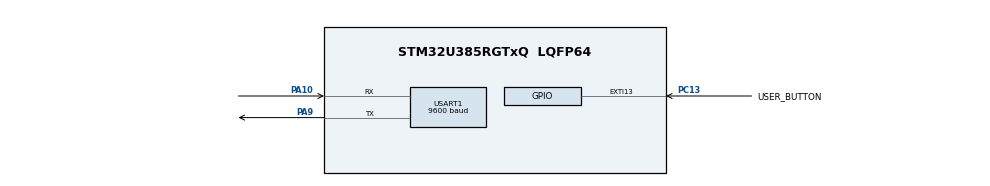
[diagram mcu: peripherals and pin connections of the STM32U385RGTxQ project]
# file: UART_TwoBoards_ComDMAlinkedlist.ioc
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CORTEX_M33_NS.userName=CORTEX_M33
GPDMA1.LINKALLOCATEDPORT_GPDMACH0=DMA_LINK_ALLOCATED_PORT1
GPDMA1.LINKALLOCATEDPORT_GPDMACH1=DMA_LINK_ALLOCATED_PORT1
Linkedlist.MDMA_Channel0.GP_SW.0.BlkHWRequest=DMA_BREQ_SINGLE_BURST
Linkedlist.MDMA_Channel0.GP_SW.0.DataHandling=NONE
Linkedlist.MDMA_Channel0.GP_SW.0.DataSize=0
Linkedlist.MDMA_Channel0.GP_SW.0.DestBurstLength=1
Linkedlist.MDMA_Channel0.GP_SW.0.DestDataWidth=DMA_DEST_DATAWIDTH_BYTE
Linkedlist.MDMA_Channel0.GP_SW.0.DestInc=DMA_DINC_FIXED
Linkedlist.MDMA_Channel0.GP_SW.0.Direction=DMA_MEMORY_TO_PERIPH
Linkedlist.MDMA_Channel0.GP_SW.0.DstAddress=0
Linkedlist.MDMA_Channel0.GP_SW.0.Instance=MDMA_Channel0
Linkedlist.MDMA_Channel0.GP_SW.0.LL_MASTERDMA=GPDMA
Linkedlist.MDMA_Channel0.GP_SW.0.LL_NAME=UART_Tx_Queue
Linkedlist.MDMA_Channel0.GP_SW.0.LL_TYPE=LINEAR
Linkedlist.MDMA_Channel0.GP_SW.0.Mode=DMA_NORMAL
Linkedlist.MDMA_Channel0.GP_SW.0.NODE_NAME=Node1_tx
Linkedlist.MDMA_Channel0.GP_SW.0.Requestforcodegen=GPDMA1_REQUEST_USART1_TX
Linkedlist.MDMA_Channel0.GP_SW.0.SrcAddress=0
Linkedlist.MDMA_Channel0.GP_SW.0.SrcBurstLength=1
Linkedlist.MDMA_Channel0.GP_SW.0.SrcDataWidth=DMA_SRC_DATAWIDTH_BYTE
Linkedlist.MDMA_Channel0.GP_SW.0.SrcInc=DMA_SINC_INCREMENTED
Linkedlist.MDMA_Channel0.GP_SW.0.TransferAllocatedPortSrc=DMA_SRC_ALLOCATED_PORT0
Linkedlist.MDMA_Channel0.GP_SW.0.TransferEventMode=DMA_TCEM_LAST_LL_ITEM_TRANSFER
Linkedlist.MDMA_Channel0.GP_SW.0.TriggerPolarity=DMA_TRIG_POLARITY_MASKED
Linkedlist.MDMA_Channel0.GP_SW.1.BlkHWRequest=DMA_BREQ_SINGLE_BURST
Linkedlist.MDMA_Channel0.GP_SW.1.DataHandling=NONE
Linkedlist.MDMA_Channel0.GP_SW.1.DataSize=128
Linkedlist.MDMA_Channel0.GP_SW.1.DestBurstLength=1
Linkedlist.MDMA_Channel0.GP_SW.1.DestDataWidth=DMA_DEST_DATAWIDTH_BYTE
Linkedlist.MDMA_Channel0.GP_SW.1.DestInc=DMA_DINC_FIXED
Linkedlist.MDMA_Channel0.GP_SW.1.Direction=DMA_MEMORY_TO_PERIPH
Linkedlist.MDMA_Channel0.GP_SW.1.DstAddress=(uint32_t)&huart1.Instance->TDR
Linkedlist.MDMA_Channel0.GP_SW.1.Instance=MDMA_Channel0
Linkedlist.MDMA_Channel0.GP_SW.1.LL_MASTERDMA=GPDMA
Linkedlist.MDMA_Channel0.GP_SW.1.LL_NAME=UART_Tx_Queue
Linkedlist.MDMA_Channel0.GP_SW.1.LL_TYPE=LINEAR
Linkedlist.MDMA_Channel0.GP_SW.1.Mode=DMA_NORMAL
Linkedlist.MDMA_Channel0.GP_SW.1.NODE_NAME=Node2_tx
Linkedlist.MDMA_Channel0.GP_SW.1.Requestforcodegen=GPDMA1_REQUEST_USART1_TX
Linkedlist.MDMA_Channel0.GP_SW.1.SrcAddress=(uint32_t) aTxBuffer1
Linkedlist.MDMA_Channel0.GP_SW.1.SrcBurstLength=1
Linkedlist.MDMA_Channel0.GP_SW.1.SrcDataWidth=DMA_SRC_DATAWIDTH_BYTE
Linkedlist.MDMA_Channel0.GP_SW.1.SrcInc=DMA_SINC_INCREMENTED
Linkedlist.MDMA_Channel0.GP_SW.1.TransferAllocatedPortSrc=DMA_SRC_ALLOCATED_PORT0
Linkedlist.MDMA_Channel0.GP_SW.1.TransferEventMode=DMA_TCEM_LAST_LL_ITEM_TRANSFER
Linkedlist.MDMA_Channel0.GP_SW.1.TriggerPolarity=DMA_TRIG_POLARITY_MASKED
Linkedlist.MDMA_Channel0.GP_SW.2.BlkHWRequest=DMA_BREQ_SINGLE_BURST
Linkedlist.MDMA_Channel0.GP_SW.2.DataHandling=NONE
Linkedlist.MDMA_Channel0.GP_SW.2.DataSize=128
Linkedlist.MDMA_Channel0.GP_SW.2.DestBurstLength=1
Linkedlist.MDMA_Channel0.GP_SW.2.DestDataWidth=DMA_DEST_DATAWIDTH_BYTE
Linkedlist.MDMA_Channel0.GP_SW.2.DestInc=DMA_DINC_FIXED
Linkedlist.MDMA_Channel0.GP_SW.2.Direction=DMA_MEMORY_TO_PERIPH
Linkedlist.MDMA_Channel0.GP_SW.2.DstAddress=(uint32_t)&huart1.Instance->TDR
Linkedlist.MDMA_Channel0.GP_SW.2.Instance=MDMA_Channel0
Linkedlist.MDMA_Channel0.GP_SW.2.LL_MASTERDMA=GPDMA
Linkedlist.MDMA_Channel0.GP_SW.2.LL_NAME=UART_Tx_Queue
Linkedlist.MDMA_Channel0.GP_SW.2.LL_TYPE=LINEAR
Linkedlist.MDMA_Channel0.GP_SW.2.Mode=DMA_NORMAL
Linkedlist.MDMA_Channel0.GP_SW.2.NODE_NAME=Node3_tx
Linkedlist.MDMA_Channel0.GP_SW.2.Requestforcodegen=GPDMA1_REQUEST_USART1_TX
Linkedlist.MDMA_Channel0.GP_SW.2.SrcAddress=(uint32_t) aTxBuffer2
Linkedlist.MDMA_Channel0.GP_SW.2.SrcBurstLength=1
Linkedlist.MDMA_Channel0.GP_SW.2.SrcDataWidth=DMA_SRC_DATAWIDTH_BYTE
Linkedlist.MDMA_Channel0.GP_SW.2.SrcInc=DMA_SINC_INCREMENTED
Linkedlist.MDMA_Channel0.GP_SW.2.TransferAllocatedPortSrc=DMA_SRC_ALLOCATED_PORT0
Linkedlist.MDMA_Channel0.GP_SW.2.TransferEventMode=DMA_TCEM_LAST_LL_ITEM_TRANSFER
Linkedlist.MDMA_Channel0.GP_SW.2.TriggerPolarity=DMA_TRIG_POLARITY_MASKED
Linkedlist.MDMA_Channel0.Request0=GP_SW
Linkedlist.MDMA_Channel0.Request1=GP_SW
Linkedlist.MDMA_Channel0.Request2=GP_SW
Linkedlist.MDMA_Channel0.RequestsNb=3
Linkedlist.MDMA_Channel1.GP_SW.0.BlkHWRequest=DMA_BREQ_SINGLE_BURST
Linkedlist.MDMA_Channel1.GP_SW.0.DataHandling=NONE
Linkedlist.MDMA_Channel1.GP_SW.0.DataSize=0
Linkedlist.MDMA_Channel1.GP_SW.0.DestBurstLength=1
Linkedlist.MDMA_Channel1.GP_SW.0.DestDataWidth=DMA_DEST_DATAWIDTH_BYTE
Linkedlist.MDMA_Channel1.GP_SW.0.DestInc=DMA_DINC_INCREMENTED
Linkedlist.MDMA_Channel1.GP_SW.0.Direction=DMA_PERIPH_TO_MEMORY
Linkedlist.MDMA_Channel1.GP_SW.0.DstAddress=0
Linkedlist.MDMA_Channel1.GP_SW.0.Instance=MDMA_Channel1
Linkedlist.MDMA_Channel1.GP_SW.0.LL_MASTERDMA=GPDMA
Linkedlist.MDMA_Channel1.GP_SW.0.LL_NAME=UART_Rx_Queue
Linkedlist.MDMA_Channel1.GP_SW.0.LL_TYPE=LINEAR
Linkedlist.MDMA_Channel1.GP_SW.0.Mode=DMA_NORMAL
Linkedlist.MDMA_Channel1.GP_SW.0.NODE_NAME=Node1_rx
Linkedlist.MDMA_Channel1.GP_SW.0.Requestforcodegen=GPDMA1_REQUEST_USART1_RX
Linkedlist.MDMA_Channel1.GP_SW.0.SrcAddress=0
Linkedlist.MDMA_Channel1.GP_SW.0.SrcBurstLength=1
Linkedlist.MDMA_Channel1.GP_SW.0.SrcDataWidth=DMA_SRC_DATAWIDTH_BYTE
Linkedlist.MDMA_Channel1.GP_SW.0.SrcInc=DMA_SINC_FIXED
Linkedlist.MDMA_Channel1.GP_SW.0.TransferAllocatedPortSrc=DMA_SRC_ALLOCATED_PORT0
Linkedlist.MDMA_Channel1.GP_SW.0.TransferEventMode=DMA_TCEM_LAST_LL_ITEM_TRANSFER
Linkedlist.MDMA_Channel1.GP_SW.0.TriggerPolarity=DMA_TRIG_POLARITY_MASKED
Linkedlist.MDMA_Channel1.GP_SW.1.BlkHWRequest=DMA_BREQ_SINGLE_BURST
Linkedlist.MDMA_Channel1.GP_SW.1.DataHandling=NONE
Linkedlist.MDMA_Channel1.GP_SW.1.DataSize=128
Linkedlist.MDMA_Channel1.GP_SW.1.DestBurstLength=1
Linkedlist.MDMA_Channel1.GP_SW.1.DestDataWidth=DMA_DEST_DATAWIDTH_BYTE
Linkedlist.MDMA_Channel1.GP_SW.1.DestInc=DMA_DINC_INCREMENTED
Linkedlist.MDMA_Channel1.GP_SW.1.Direction=DMA_PERIPH_TO_MEMORY
Linkedlist.MDMA_Channel1.GP_SW.1.DstAddress=(uint32_t) aRxBuffer1
Linkedlist.MDMA_Channel1.GP_SW.1.Instance=MDMA_Channel1
Linkedlist.MDMA_Channel1.GP_SW.1.LL_MASTERDMA=GPDMA
Linkedlist.MDMA_Channel1.GP_SW.1.LL_NAME=UART_Rx_Queue
Linkedlist.MDMA_Channel1.GP_SW.1.LL_TYPE=LINEAR
Linkedlist.MDMA_Channel1.GP_SW.1.Mode=DMA_NORMAL
Linkedlist.MDMA_Channel1.GP_SW.1.NODE_NAME=Node2_rx
Linkedlist.MDMA_Channel1.GP_SW.1.Requestforcodegen=GPDMA1_REQUEST_USART1_RX
Linkedlist.MDMA_Channel1.GP_SW.1.SrcAddress=(uint32_t)&huart1.Instance->RDR
Linkedlist.MDMA_Channel1.GP_SW.1.SrcBurstLength=1
Linkedlist.MDMA_Channel1.GP_SW.1.SrcDataWidth=DMA_SRC_DATAWIDTH_BYTE
Linkedlist.MDMA_Channel1.GP_SW.1.SrcInc=DMA_SINC_FIXED
Linkedlist.MDMA_Channel1.GP_SW.1.TransferAllocatedPortSrc=DMA_SRC_ALLOCATED_PORT0
Linkedlist.MDMA_Channel1.GP_SW.1.TransferEventMode=DMA_TCEM_LAST_LL_ITEM_TRANSFER
Linkedlist.MDMA_Channel1.GP_SW.1.TriggerPolarity=DMA_TRIG_POLARITY_MASKED
Linkedlist.MDMA_Channel1.GP_SW.2.BlkHWRequest=DMA_BREQ_SINGLE_BURST
Linkedlist.MDMA_Channel1.GP_SW.2.DataHandling=NONE
Linkedlist.MDMA_Channel1.GP_SW.2.DataSize=128
Linkedlist.MDMA_Channel1.GP_SW.2.DestBurstLength=1
Linkedlist.MDMA_Channel1.GP_SW.2.DestDataWidth=DMA_DEST_DATAWIDTH_BYTE
Linkedlist.MDMA_Channel1.GP_SW.2.DestInc=DMA_DINC_INCREMENTED
Linkedlist.MDMA_Channel1.GP_SW.2.Direction=DMA_PERIPH_TO_MEMORY
Linkedlist.MDMA_Channel1.GP_SW.2.DstAddress=(uint32_t) aRxBuffer2
Linkedlist.MDMA_Channel1.GP_SW.2.Instance=MDMA_Channel1
Linkedlist.MDMA_Channel1.GP_SW.2.LL_MASTERDMA=GPDMA
Linkedlist.MDMA_Channel1.GP_SW.2.LL_NAME=UART_Rx_Queue
Linkedlist.MDMA_Channel1.GP_SW.2.LL_TYPE=LINEAR
Linkedlist.MDMA_Channel1.GP_SW.2.Mode=DMA_NORMAL
Linkedlist.MDMA_Channel1.GP_SW.2.NODE_NAME=Node3_rx
Linkedlist.MDMA_Channel1.GP_SW.2.Requestforcodegen=GPDMA1_REQUEST_USART1_RX
Linkedlist.MDMA_Channel1.GP_SW.2.SrcAddress=(uint32_t)&huart1.Instance->RDR
Linkedlist.MDMA_Channel1.GP_SW.2.SrcBurstLength=1
Linkedlist.MDMA_Channel1.GP_SW.2.SrcDataWidth=DMA_SRC_DATAWIDTH_BYTE
Linkedlist.MDMA_Channel1.GP_SW.2.SrcInc=DMA_SINC_FIXED
Linkedlist.MDMA_Channel1.GP_SW.2.TransferAllocatedPortSrc=DMA_SRC_ALLOCATED_PORT0
Linkedlist.MDMA_Channel1.GP_SW.2.TransferEventMode=DMA_TCEM_LAST_LL_ITEM_TRANSFER
Linkedlist.MDMA_Channel1.GP_SW.2.TriggerPolarity=DMA_TRIG_POLARITY_MASKED
Linkedlist.MDMA_Channel1.Request0=GP_SW
Linkedlist.MDMA_Channel1.Request1=GP_SW
Linkedlist.MDMA_Channel1.Request2=GP_SW
Linkedlist.MDMA_Channel1.RequestsNb=3
Linkedlist.RequestSet0=MDMA_Channel0
Linkedlist.RequestSet1=MDMA_Channel1
Linkedlist.RequestSetsNb=2
Mcu.Family=STM32U3
Mcu.Name=STM32U385RGTxQ
Mcu.Package=LQFP64
NVIC.EXTI13_IRQn=true\:0\:0\:false\:false\:true\:true\:true\:true
NVIC.GPDMA1_Channel0_IRQn=true\:0\:0\:false\:false\:true\:true\:true\:true
NVIC.GPDMA1_Channel1_IRQn=true\:0\:0\:false\:false\:true\:true\:true\:true
NVIC.PriorityGroup=NVIC_PRIORITYGROUP_4
NVIC.USART1_IRQn=true\:0\:0\:false\:false\:true\:true\:true\:true
PA10.GPIO_PuPd=GPIO_PULLUP
PA10.GPIO_Speed=GPIO_SPEED_FREQ_VERY_HIGH
PA10.Mode=Asynchronous
PA10.Signal=USART1_RX
PA9.GPIO_PuPd=GPIO_PULLUP
PA9.GPIO_Speed=GPIO_SPEED_FREQ_VERY_HIGH
PA9.Mode=Asynchronous
PA9.Signal=USART1_TX
PC13.GPIO_Label=USER_BUTTON
PC13.GPIO_ModeDefaultEXTI=GPIO_MODE_IT_RISING
PC13.GPIO_PuPd=GPIO_PULLDOWN
PC13.Signal=GPXTI13
ProjectManager.HeapSize=0x200
ProjectManager.StackSize=0x400
ProjectManager.TargetToolchain=EWARM V9.20
RCC.ADCFreq_Value=96000000
RCC.AHBFreq_Value=96000000
RCC.APB1Freq_Value=96000000
RCC.APB1TimFreq_Value=96000000
RCC.APB2Freq_Value=96000000
RCC.APB2TimFreq_Value=96000000
RCC.APB3Freq_Value=96000000
RCC.CortexFreq_Value=12000000
RCC.HCLKFreq_Value=96000000
RCC.HSE_VALUE=16000000
RCC.HSI48_VALUE=48000000
RCC.HSI_VALUE=16000000
RCC.LSE_VALUE=32768
RCC.LSIDIV_VALUE=32000
RCC.MSISDIV=RCC_MSI_DIV1
RCC.SYSCLKFreq_VALUE=96000000
RCC.USBFreq_Value=96000000
USART1.BaudRate=9600
USART1.ClockPrescaler=PRESCALER_DIV1
USART1.OneBitSampling=UART_ONE_BIT_SAMPLE_DISABLE
USART1.VirtualMode-Asynchronous=VM_ASYNC
VP_GPDMA1_VS_GPDMACH0.Mode=LINKEDLIST_GPDMACH0
VP_GPDMA1_VS_GPDMACH1.Mode=LINKEDLIST_GPDMACH1
VP_ICACHE_VS_ICACHE.Mode=DirectMappedCache
VP_PWR_VS_DBSignals.Mode=DisableDeadBatterySignals
VP_PWR_VS_LPOM.Mode=PowerOptimisation
VP_PWR_VS_SECSignals.Mode=Security/Privilege
board=custom

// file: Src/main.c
/* USER CODE BEGIN Header */
/**
  ******************************************************************************
  * @file           : main.c
  * @brief          : Main program body
  ******************************************************************************
  * @attention
  *
  * Copyright (c) 2024 STMicroelectronics.
  * All rights reserved.
  *
  * This software is licensed under terms that can be found in the LICENSE file
  * in the root directory of this software component.
  * If no LICENSE file comes with this software, it is provided AS-IS.
  *
  ******************************************************************************
  */
/* USER CODE END Header */
#include "main.h"

/* USER CODE BEGIN Includes */
#include "linked_list.h"
/* USER CODE END Includes */

/* USER CODE BEGIN PD */
//#define TRANSMITTER_BOARD
/* USER CODE END PD */

DMA_HandleTypeDef handle_GPDMA1_Channel1;
DMA_HandleTypeDef handle_GPDMA1_Channel0;

UART_HandleTypeDef huart1;

/* USER CODE BEGIN PV */
__IO ITStatus UartReady = RESET;
__IO uint32_t UserButtonStatus = 0;  /* set to 1 after User Button interrupt  */
extern DMA_QListTypeDef UART_Tx_Queue;
extern DMA_QListTypeDef UART_Rx_Queue;

/* Buffers used for transmission :
   Size should be a Multiple of cache line size (32 bytes) */
ALIGN_32BYTES (uint8_t aTxBuffer0[]) = "0*****UART_TwoBoards communication based on DMA Linkedlist*****  *****UART_TwoBoards communication based on DMA Linkedlist*****0";
ALIGN_32BYTES (uint8_t aTxBuffer1[]) = "1*****UART_TwoBoards communication based on DMA Linkedlist*****  *****UART_TwoBoards communication based on DMA Linkedlist*****1";
ALIGN_32BYTES (uint8_t aTxBuffer2[]) = "2*****UART_TwoBoards communication based on DMA Linkedlist*****  *****UART_TwoBoards communication based on DMA Linkedlist*****2";

/* Buffer used for reception :
   Size should be a Multiple of cache line size (32 bytes) */
ALIGN_32BYTES (uint8_t aRxBuffer0[RXBUFFERSIZE]);
ALIGN_32BYTES (uint8_t aRxBuffer1[RXBUFFERSIZE]);
ALIGN_32BYTES (uint8_t aRxBuffer2[RXBUFFERSIZE]);
/* USER CODE END PV */

void SystemClock_Config(void);
static void MX_GPIO_Init(void);
static void MX_GPDMA1_Init(void);
static void MX_USART1_UART_Init(void);
static void MX_ICACHE_Init(void);
/* USER CODE BEGIN PFP */
static uint16_t Buffercmp(uint8_t* pBuffer1, uint8_t* pBuffer2, uint16_t BufferLength);
/* USER CODE END PFP */

int main(void)
{

  /* USER CODE BEGIN 1 */

  /* STM32U3xx HAL library initialization:
       - Configure the Flash prefetch
       - Configure the Systick to generate an interrupt each 1 msec
       - Set NVIC Group Priority to 3
       - Low Level Initialization
     */
  /* USER CODE END 1 */

  /* MCU Configuration--------------------------------------------------------*/

  /* Reset of all peripherals, Initializes the Flash interface and the Systick. */
  HAL_Init();

  /* Configure the system clock */
  SystemClock_Config();

  /* USER CODE BEGIN SysInit */
  /* Configure LD2 */
  BSP_LED_Init(LD2);

  /* USER CODE END SysInit */

  /* Initialize all configured peripherals */
  MX_GPIO_Init();
  MX_GPDMA1_Init();
  MX_USART1_UART_Init();
  MX_ICACHE_Init();
  /* USER CODE BEGIN 2 */

  MX_UART_Tx_Queue_Config();
  MX_UART_Rx_Queue_Config();
  /* Link UART queue to DMA channel */
  HAL_DMAEx_List_LinkQ(&handle_GPDMA1_Channel1, &UART_Tx_Queue);

  /* Associate the initialized GPDMA handle to the UART handle */
  __HAL_LINKDMA(&huart1, hdmatx, handle_GPDMA1_Channel1);

  /* Link UART queue to DMA channel */
  HAL_DMAEx_List_LinkQ(&handle_GPDMA1_Channel0, &UART_Rx_Queue);

  /* Associate the initialized GPDMA handle to the UART handle */
  __HAL_LINKDMA(&huart1, hdmarx, handle_GPDMA1_Channel0);

#ifdef TRANSMITTER_BOARD

  /* Configure User push-button in Interrupt mode */
  BSP_PB_Init(BUTTON_USER, BUTTON_MODE_EXTI);

  /* Wait for User push-button press before starting the Communication.
     In the meantime, LD2 is blinking */
  while(UserButtonStatus == 0)
  {
      /* Toggle LD2 */
      BSP_LED_Toggle(LD2);
      HAL_Delay(100);
  }

  BSP_LED_Off(LD2);

  /* The board sends the message and expects to receive it back */

  /*##-2- Start the transmission process #####################################*/
  /* While the UART in reception process, user can transmit data through
     "aTxBuffer" buffer */
  if(HAL_UART_Transmit_DMA(&huart1, (uint8_t*)aTxBuffer0, TXBUFFERSIZE)!= HAL_OK)
  {
    Error_Handler();
  }

  /*##-3- Wait for the end of the transfer ###################################*/
  while (UartReady != SET)
  {
  }

  /* Reset transmission flag */
  UartReady = RESET;

  /*##-4- Put UART peripheral in reception process ###########################*/
  if(HAL_UART_Receive_DMA(&huart1, (uint8_t *)aRxBuffer0, RXBUFFERSIZE) != HAL_OK)
  {
    Error_Handler();
  }

#else

  /* The board receives the message and sends it back */

  /*##-2- Put UART peripheral in reception process ###########################*/
  if(HAL_UART_Receive_DMA(&huart1, (uint8_t *)aRxBuffer0, RXBUFFERSIZE) != HAL_OK)
  {
    Error_Handler();
  }

  /*##-3- Wait for the end of the transfer ###################################*/
  /* While waiting for message to come from the other board, LD2 is
     blinking according to the following pattern: a double flash every half-second */
  while (UartReady != SET)
  {
      BSP_LED_On(LD2);
      HAL_Delay(100);
      BSP_LED_Off(LD2);
      HAL_Delay(100);
      BSP_LED_On(LD2);
      HAL_Delay(100);
      BSP_LED_Off(LD2);
      HAL_Delay(500);
  }

  /* Reset transmission flag */
  UartReady = RESET;
  BSP_LED_Off(LD2);

  /*##-4- Start the transmission process #####################################*/
  if(HAL_UART_Transmit_DMA(&huart1, (uint8_t*)aTxBuffer0, TXBUFFERSIZE)!= HAL_OK)
  {
    Error_Handler();
  }

#endif /* TRANSMITTER_BOARD */

  /*##-5- Wait for the end of the transfer ###################################*/
  while (UartReady != SET)
  {
  }

  /* Reset transmission flag */
  UartReady = RESET;

  /*##-6- Compare the sent and received buffers ##############################*/
  if((Buffercmp((uint8_t*)aTxBuffer0,(uint8_t*)aRxBuffer0,RXBUFFERSIZE) != 0) ||\
     (Buffercmp((uint8_t*)aTxBuffer1,(uint8_t*)aRxBuffer1,RXBUFFERSIZE) != 0) ||\
     (Buffercmp((uint8_t*)aTxBuffer2,(uint8_t*)aRxBuffer2,RXBUFFERSIZE) != 0))
  {
    Error_Handler();
  }

  /* Turn on LD2 if test passes then enter infinite loop */
  BSP_LED_On(LD2);

  /* USER CODE END 2 */

  /* Infinite loop */
  while (1)
  {

  }
}

void SystemClock_Config(void)
{
  RCC_OscInitTypeDef RCC_OscInitStruct = {0};
  RCC_ClkInitTypeDef RCC_ClkInitStruct = {0};

  /** Enable Epod Booster
  */
  if (HAL_RCCEx_EpodBoosterClkConfig(RCC_EPODBOOSTER_SOURCE_MSIS, RCC_EPODBOOSTER_DIV1) != HAL_OK)
  {
    Error_Handler();
  }

  if (HAL_PWREx_EnableEpodBooster() != HAL_OK)
  {
    Error_Handler();
  }

  /** Configure the main internal regulator output voltage
  */
  if (HAL_PWREx_ControlVoltageScaling(PWR_REGULATOR_VOLTAGE_SCALE1) != HAL_OK)
  {
    Error_Handler();
  }

  /** Set Flash latency before increasing MSIS
  */
  __HAL_FLASH_SET_LATENCY(FLASH_LATENCY_2);

  /** Initializes the CPU, AHB and APB buses clocks
  */
  RCC_OscInitStruct.OscillatorType = RCC_OSCILLATORTYPE_MSIS;
  RCC_OscInitStruct.MSISState = RCC_MSI_ON;
  RCC_OscInitStruct.MSISSource = RCC_MSI_RC0;
  RCC_OscInitStruct.MSISDiv = RCC_MSI_DIV1;
  if (HAL_RCC_OscConfig(&RCC_OscInitStruct) != HAL_OK)
  {
    Error_Handler();
  }

  /** Initializes the CPU, AHB and APB buses clocks
  */
  RCC_ClkInitStruct.ClockType = RCC_CLOCKTYPE_HCLK|RCC_CLOCKTYPE_SYSCLK
                              |RCC_CLOCKTYPE_PCLK1|RCC_CLOCKTYPE_PCLK2
                              |RCC_CLOCKTYPE_PCLK3;
  RCC_ClkInitStruct.SYSCLKSource = RCC_SYSCLKSOURCE_MSIS;
  RCC_ClkInitStruct.AHBCLKDivider = RCC_SYSCLK_DIV1;
  RCC_ClkInitStruct.APB1CLKDivider = RCC_HCLK_DIV1;
  RCC_ClkInitStruct.APB2CLKDivider = RCC_HCLK_DIV1;
  RCC_ClkInitStruct.APB3CLKDivider = RCC_HCLK_DIV1;

  if (HAL_RCC_ClockConfig(&RCC_ClkInitStruct, FLASH_LATENCY_2) != HAL_OK)
  {
    Error_Handler();
  }
}

static void MX_GPDMA1_Init(void)
{

  /* Peripheral clock enable */
  __HAL_RCC_GPDMA1_CLK_ENABLE();

  /* GPDMA1 interrupt Init */
    HAL_NVIC_SetPriority(GPDMA1_Channel0_IRQn, 0, 0);
    HAL_NVIC_EnableIRQ(GPDMA1_Channel0_IRQn);
    HAL_NVIC_SetPriority(GPDMA1_Channel1_IRQn, 0, 0);
    HAL_NVIC_EnableIRQ(GPDMA1_Channel1_IRQn);

  handle_GPDMA1_Channel1.Instance = GPDMA1_Channel1;
  handle_GPDMA1_Channel1.InitLinkedList.Priority = DMA_LOW_PRIORITY_LOW_WEIGHT;
  handle_GPDMA1_Channel1.InitLinkedList.LinkStepMode = DMA_LSM_FULL_EXECUTION;
  handle_GPDMA1_Channel1.InitLinkedList.LinkAllocatedPort = DMA_LINK_ALLOCATED_PORT1;
  handle_GPDMA1_Channel1.InitLinkedList.TransferEventMode = DMA_TCEM_LAST_LL_ITEM_TRANSFER;
  handle_GPDMA1_Channel1.InitLinkedList.LinkedListMode = DMA_LINKEDLIST_NORMAL;
  if (HAL_DMAEx_List_Init(&handle_GPDMA1_Channel1) != HAL_OK)
  {
    Error_Handler();
  }
  if (HAL_DMA_ConfigChannelAttributes(&handle_GPDMA1_Channel1, DMA_CHANNEL_NPRIV) != HAL_OK)
  {
    Error_Handler();
  }
  handle_GPDMA1_Channel0.Instance = GPDMA1_Channel0;
  handle_GPDMA1_Channel0.InitLinkedList.Priority = DMA_LOW_PRIORITY_LOW_WEIGHT;
  handle_GPDMA1_Channel0.InitLinkedList.LinkStepMode = DMA_LSM_FULL_EXECUTION;
  handle_GPDMA1_Channel0.InitLinkedList.LinkAllocatedPort = DMA_LINK_ALLOCATED_PORT1;
  handle_GPDMA1_Channel0.InitLinkedList.TransferEventMode = DMA_TCEM_LAST_LL_ITEM_TRANSFER;
  handle_GPDMA1_Channel0.InitLinkedList.LinkedListMode = DMA_LINKEDLIST_NORMAL;
  if (HAL_DMAEx_List_Init(&handle_GPDMA1_Channel0) != HAL_OK)
  {
    Error_Handler();
  }
  if (HAL_DMA_ConfigChannelAttributes(&handle_GPDMA1_Channel0, DMA_CHANNEL_NPRIV) != HAL_OK)
  {
    Error_Handler();
  }

}

static void MX_ICACHE_Init(void)
{

  /** Enable instruction cache in 1-way (direct mapped cache)
  */
  if (HAL_ICACHE_ConfigAssociativityMode(ICACHE_1WAY) != HAL_OK)
  {
    Error_Handler();
  }
  if (HAL_ICACHE_Enable() != HAL_OK)
  {
    Error_Handler();
  }

}

static void MX_USART1_UART_Init(void)
{

  huart1.Instance = USART1;
  huart1.Init.BaudRate = 9600;
  huart1.Init.WordLength = UART_WORDLENGTH_8B;
  huart1.Init.StopBits = UART_STOPBITS_1;
  huart1.Init.Parity = UART_PARITY_NONE;
  huart1.Init.Mode = UART_MODE_TX_RX;
  huart1.Init.HwFlowCtl = UART_HWCONTROL_NONE;
  huart1.Init.OverSampling = UART_OVERSAMPLING_16;
  huart1.Init.OneBitSampling = UART_ONE_BIT_SAMPLE_DISABLE;
  huart1.Init.ClockPrescaler = UART_PRESCALER_DIV1;
  huart1.AdvancedInit.AdvFeatureInit = UART_ADVFEATURE_NO_INIT;
  if (HAL_UART_Init(&huart1) != HAL_OK)
  {
    Error_Handler();
  }
  if (HAL_UARTEx_SetTxFifoThreshold(&huart1, UART_TXFIFO_THRESHOLD_1_8) != HAL_OK)
  {
    Error_Handler();
  }
  if (HAL_UARTEx_SetRxFifoThreshold(&huart1, UART_RXFIFO_THRESHOLD_1_8) != HAL_OK)
  {
    Error_Handler();
  }
  if (HAL_UARTEx_DisableFifoMode(&huart1) != HAL_OK)
  {
    Error_Handler();
  }

}

static void MX_GPIO_Init(void)
{
  GPIO_InitTypeDef GPIO_InitStruct = {0};

  /* GPIO Ports Clock Enable */
  __HAL_RCC_GPIOC_CLK_ENABLE();
  __HAL_RCC_GPIOA_CLK_ENABLE();

  /*Configure GPIO pin : USER_BUTTON_Pin */
  GPIO_InitStruct.Pin = USER_BUTTON_Pin;
  GPIO_InitStruct.Mode = GPIO_MODE_IT_RISING;
  GPIO_InitStruct.Pull = GPIO_PULLDOWN;
  HAL_GPIO_Init(USER_BUTTON_GPIO_Port, &GPIO_InitStruct);

  /* EXTI interrupt init*/
  HAL_NVIC_SetPriority(EXTI13_IRQn, 0, 0);
  HAL_NVIC_EnableIRQ(EXTI13_IRQn);

}

/* USER CODE BEGIN 4 */
/**
  * @brief  Tx Transfer completed callback
  * @param  UartHandle: UART handle.
  * @note   This example shows a simple way to report end of DMA Tx transfer, and
  *         you can add your own implementation.
  * @retval None
  */
void HAL_UART_TxCpltCallback(UART_HandleTypeDef *UartHandle)
{
  /* Set transmission flag: transfer complete */
  UartReady = SET;

#ifdef TRANSMITTER_BOARD
  /* Turn LD2 on: Transfer in transmission process is correct */
  BSP_LED_On(LD2);
#else
	/* Turn LD2 off: Transfer in transmission process is correct */
  BSP_LED_Off(LD2);
#endif  /* TRANSMITTER_BOARD */

}

/**
  * @brief  Rx Transfer completed callback
  * @param  UartHandle: UART handle
  * @note   This example shows a simple way to report end of DMA Rx transfer, and
  *         you can add your own implementation.
  * @retval None
  */
void HAL_UART_RxCpltCallback(UART_HandleTypeDef *UartHandle)
{
  /* Set transmission flag: transfer complete */
  UartReady = SET;

#ifdef TRANSMITTER_BOARD
  /* Turn LD2 off: Transfer in reception process is correct */
  BSP_LED_Off(LD2);
#else
  /* Turn LD2 on: Transfer in reception process is correct */
  BSP_LED_On(LD2);
#endif  /* TRANSMITTER_BOARD */

}

/**
  * @brief  UART error callbacks
  * @param  UartHandle: UART handle
  * @note   This example shows a simple way to report transfer error, and you can
  *         add your own implementation.
  * @retval None
  */
void HAL_UART_ErrorCallback(UART_HandleTypeDef *UartHandle)
{
    Error_Handler();
}

/**
  * @brief EXTI line detection callbacks
  * @param GPIO_Pin: Specifies the pins connected EXTI line
  * @retval None
  */
void HAL_GPIO_EXTI_Rising_Callback(uint16_t GPIO_Pin)
{
  if (GPIO_Pin == BUTTON_USER_PIN)
  {
    UserButtonStatus = 1;
  }
}
/**
  * @brief  Compares two buffers.
  * @param  pBuffer1, pBuffer2: buffers to be compared.
  * @param  BufferLength: buffer's length
  * @retval 0  : pBuffer1 identical to pBuffer2
  *         >0 : pBuffer1 differs from pBuffer2
  */
static uint16_t Buffercmp(uint8_t* pBuffer1, uint8_t* pBuffer2, uint16_t BufferLength)
{
  while (BufferLength--)
  {
    if ((*pBuffer1) != *pBuffer2)
    {
      return BufferLength;
    }
    pBuffer1++;
    pBuffer2++;
  }

  return 0;
}

/* USER CODE END 4 */

void Error_Handler(void)
{
  /* USER CODE BEGIN Error_Handler_Debug */
  /* Turn LD2 on */
  BSP_LED_Off(LD2);
  __disable_irq();
  while (1)
  {
  }
  /* USER CODE END Error_Handler_Debug */
}

#ifdef  USE_FULL_ASSERT
/**
  * @brief  Reports the name of the source file and the source line number
  *         where the assert_param error has occurred.
  * @param  file: pointer to the source file name
  * @param  line: assert_param error line source number
  * @retval None
  */
void assert_failed(uint8_t *file, uint32_t line)
{
  /* USER CODE BEGIN 6 */
  /* User can add his own implementation to report the file name and line number,
     ex: printf("Wrong parameters value: file %s on line %d\r\n", file, line) */
  /* Infinite Loop */
  while (1)
  {
  }
  /* USER CODE END 6 */
}
#endif /* USE_FULL_ASSERT */
